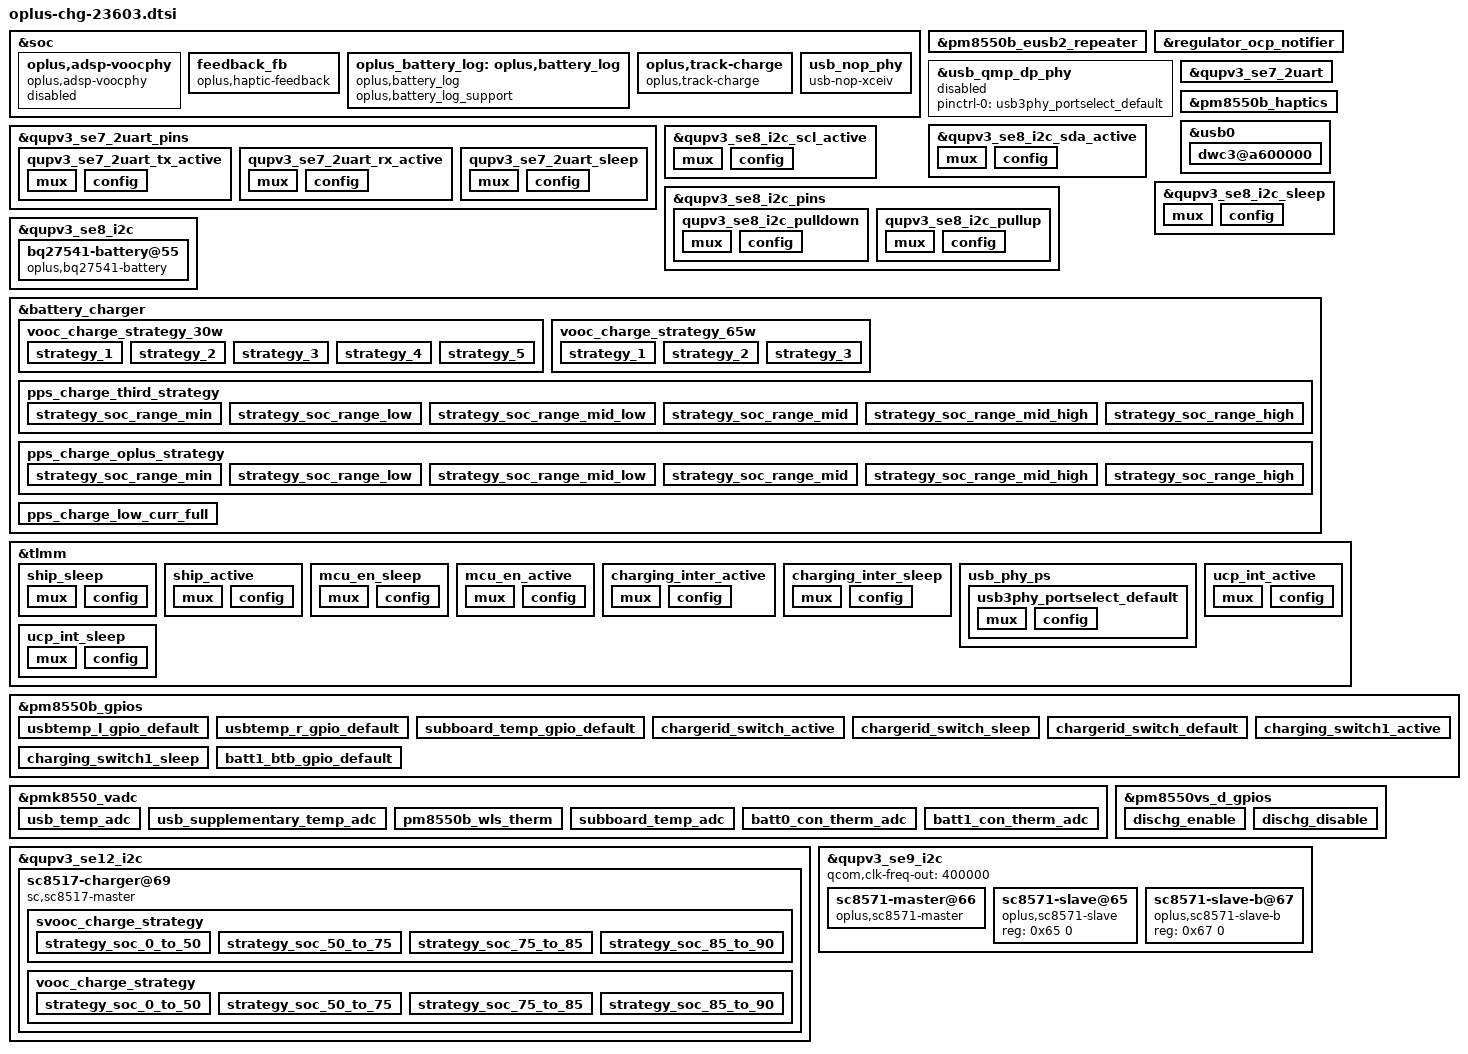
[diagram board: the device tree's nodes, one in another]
#include "oplus_chg_8550.h"
#include <dt-bindings/phy/qcom,usb3-4nm-qmp-combo.h>

//#ifdef OPLUS_FEATURE_CHG_BASIC /* BSP.CHG.Basic, 2020/05/20, sjc Add for charging */
&soc {
	oplus,adsp-voocphy {
		status = "disabled";
		compatible = "oplus,adsp-voocphy";
	};
};

&pm8550b_eusb2_repeater {
	qcom,param-override-seq = <0x00 0x50 0x0D 0x51 0x07 0x53 0x03 0x54
			0x03 0x55 0x00 0x56 0x07 0x57 0x2 0x58 0x3 0x59 0x1 0x5A 0x2 0x5B>;
	qcom,param-override-seq-host = <0x00 0x50 0x06 0x51 0x07 0x53 0x03 0x54
			0x00 0x55 0x00 0x56 0x02 0x57 0x2 0x58 0x3 0x59 0x1 0x5A 0x2 0x5B>;
};

&regulator_ocp_notifier {
	periph-1cb-supply = <0>;
	periph-1cc-supply = <0>;
	periph-1cd-supply = <0>;
	periph-4c1-supply = <0>;
	periph-4c3-supply = <0>;
};

&usb_qmp_dp_phy {
	pinctrl-names = "default";
	pinctrl-0 = <&usb3phy_portselect_default>;
	status = "disabled";
};

&qupv3_se7_2uart_pins {
	qupv3_se7_2uart_tx_active: qupv3_se7_2uart_tx_active {
		mux {
			pins = "gpio26";
			function = "qup1_se7_l2";
		};

		config {
			pins = "gpio26";
			drive-strength = <2>;
			bias-disable;
		};
	};

	qupv3_se7_2uart_rx_active: qupv3_se7_2uart_rx_active {
		mux {
			pins = "gpio27";
			function = "qup1_se7_l3";
		};

		config {
			pins = "gpio27";
			drive-strength = <2>;
			bias-disable;
		};
	};

	qupv3_se7_2uart_sleep: qupv3_se7_2uart_sleep {
		mux {
			pins = "gpio26", "gpio27";
			function = "gpio";
		};

		config {
			pins = "gpio26", "gpio27";
			drive-strength = <2>;
			bias-pull-down;
			input-enable;
		};
	};
};

&qupv3_se7_2uart {
	pinctrl-names = "default", "sleep";
	pinctrl-0 = <&qupv3_se7_2uart_tx_active>, <&qupv3_se7_2uart_rx_active>;
	pinctrl-1 = <&qupv3_se7_2uart_sleep>;
	status = "ok";
};

&pm8550b_haptics {
	qcom,vmax-mv = <1280>;
	qcom,cl-vmax-mv = <1280>;
	qcom,lra-period-us = <5882>;
	qcom,fifo-vmax-mv = <8000>;
	qcom,old-steady-vmax-mv = <8000>;
	qcom,cal-data-restore;
	qcom,vibrator-type = <809>;//ela0809
	qcom,drv-duty = <4>;//75%
};

&usb0 {
/delete-property/ extcon;
	dwc3@a600000 {
		usb-phy = <&eusb2_phy0>, <&usb_nop_phy>;
		maximum-speed = "high-speed";
		dr_mode = "otg";
	};
};

&qupv3_se8_i2c_sda_active {
	mux {
		pins = "gpio0";
		function = "qup2_se0_l0_mirb";
	};

	config {
		pins = "gpio0";
		drive-strength = <2>;
		bias-pull-up;
	};
};

&qupv3_se8_i2c_scl_active {
	mux {
		pins = "gpio1";
		function = "qup2_se0_l1_mirb";
	};

	config {
		pins = "gpio1";
		drive-strength = <2>;
		bias-pull-up;
	};
};

&qupv3_se8_i2c_sleep {
	mux {
		pins = "gpio0", "gpio1";
		function = "gpio";
	};

	config {
		pins = "gpio0", "gpio1";
		drive-strength = <2>;
		bias-disable;
	};
};

&qupv3_se8_i2c_pins {
	qupv3_se8_i2c_pulldown: qupv3_se8_i2c_pulldown {
		mux {
			pins = "gpio0", "gpio1";
			function = "gpio";
		};

		config {
			pins = "gpio0", "gpio1";
			drive-strength = <2>;
			bias-pull-down;
			output-low;
		};
	};

	qupv3_se8_i2c_pullup: qupv3_se8_i2c_pullup {
		mux {
			pins = "gpio0", "gpio1";
			function = "gpio";
		};

		config {
			pins = "gpio0", "gpio1";
			drive-strength = <2>;
			bias-pull-up;
			input-enable;
		};
	};
};

&qupv3_se8_i2c {
	status = "ok";
	qcom,clk-freq-out = <100000>;

	pinctrl-names = "default", "sleep", "pulldown", "pullup";
	pinctrl-0 = <&qupv3_se8_i2c_scl_active>,<&qupv3_se8_i2c_sda_active>;
	pinctrl-1 = <&qupv3_se8_i2c_sleep>;
	pinctrl-2 = <&qupv3_se8_i2c_pulldown>;
	pinctrl-3 = <&qupv3_se8_i2c_pullup>;

	bq27541-battery@55 {
		status = "okay";
		compatible = "oplus,bq27541-battery";
		reg = <0x55>;
		qcom,modify-soc-smooth;
		qcom,modify-soc-calibration;
		qcom,batt_bq28z610;
		qcom,sha1_key_index = <1>;
	};
};

&battery_charger {
	io-channels	= <&pmk8550_vadc PM8550B_ADC5_GEN3_AMUX2_GPIO5_100K_PU>,
					<&pmk8550_vadc PM8550B_ADC5_GEN3_AMUX_THM6_GPIO10_100K_PU>,
					<&pmk8550_vadc PM8550B_ADC5_GEN3_AMUX3_GPIO6_100K_PU>,
					<&pmk8550_vadc PM8550B_ADC5_GEN3_AMUX_THM4_USB_THERM_100K_PU>,
					<&pmk8550_vadc PM8550B_ADC5_GEN3_AMUX_THM1_BATT_THERM_100K_PU>;
	io-channel-names = "usb_temp_adc",
			"usb_supplementary_temp_adc",
			"subboard_temp_adc",
			"conn_therm",
			"batt0_con_therm_adc";

	oplus,ic_type = <OPLUS_CHG_IC_BUCK>;
	oplus,ic_index = <0>;

	//for oplus chg framework:
	oplus,chg_ops = "plat-pmic";
	qcom,smart_charging_screenoff;
	qcom,voocphy_support = <2>;
	qcom,input_current_charger_ma = <2000>;
	qcom,pd_input_current_charger_ma = <2000>;
	qcom,qc_input_current_charger_ma = <2000>;

	qcom,input_current_usb_ma = <500>;

	qcom,input_current_cdp_ma = <1500>;
	qcom,input_current_led_ma = <1200>;
	qcom,input_current_led_ma_high = <1200>;
	qcom,input_current_led_ma_warm = <1500>;
	qcom,input_current_led_ma_normal = <2000>;
	qcom,led_warm_bat_decidegc = <350>;
	qcom,led_high_bat_decidegc = <370>;

	qcom,input_current_camera_ma = <1200>;

	qcom,input_current_vooc_led_ma_high = <2200>;
	qcom,input_current_vooc_led_ma_warm = <3200>;
	qcom,input_current_vooc_led_ma_normal = <3600>;
	qcom,input_current_vooc_ma_normal = <3600>;
	qcom,vooc_temp_bat_normal_decidegc = <350>;
	qcom,input_current_vooc_ma_warm = <3200>;
	qcom,vooc_temp_bat_warm_decidegc = <370>;
	qcom,input_current_vooc_ma_high = <2200>;
	qcom,vooc_temp_bat_hot_decidegc = <530>;

	qcom,charger_current_vooc_ma_normal = <3600>;

	qcom,chg_ctrl_by_calling;
	qcom,input_current_calling_ma = <1500>;

	//qcom,input_current_led_ma_overtemp = <900>;
	qcom,iterm_ma = <122>;
	qcom,recharge-mv = <100>;
	qcom,batt_capacity_mah = <4600>;/*typical capacity*/
	//qcom,batt_capacity_mah = <4400>; /*rated capacity*/

	qcom,removed_bat_decidegc = <390>;  /*<-39C*/

	qcom,cold_bat_decidegc = <200>;  /*-20C~ -10C*/
	qcom,temp_cold_vfloat_mv = <4435>;//4.45v
	qcom,temp_cold_fastchg_current_ma_high = <600>;
	qcom,temp_cold_fastchg_current_ma_low = <400>;
	qcom,temp_cold_fastchg_current_ma = <400>;

	qcom,freeze_bat_decidegc = <100>;  /*-10C~0C*/
	qcom,temp_freeze_fastchg_current_ma_high = <1800>;
	qcom,temp_freeze_fastchg_current_ma_low = <600>;
	qcom,temp_freeze_fastchg_current_ma = <600>;
	//qcom,pd_temp_freeze_fastchg_current_ma_high = <900>;
	//qcom,pd_temp_freeze_fastchg_current_ma_low = <300>;
	//qcom,qc_temp_freeze_fastchg_current_ma_high = <900>;
	//qcom,qc_temp_freeze_fastchg_current_ma_low = <300>;

	qcom,little_cold_bat_decidegc = <0>;	/*0C~5C*/
	qcom,temp_little_cold_vfloat_mv = <4435>;
	qcom,temp_little_cold_fastchg_current_ma_high = <2200>;
	qcom,temp_little_cold_fastchg_current_ma_low = <2200>;
	qcom,temp_little_cold_fastchg_current_ma = <2200>;
	qcom,pd_temp_little_cold_fastchg_current_ma_high = <4000>;
	qcom,pd_temp_little_cold_fastchg_current_ma_low = <3200>;
	qcom,qc_temp_little_cold_fastchg_current_ma_high = <4000>;
	qcom,qc_temp_little_cold_fastchg_current_ma_low = <3200>;

	qcom,cool_bat_decidegc = <50>;	/*5C~12C*/
	qcom,temp_cool_vfloat_mv = <4435>;
	qcom,temp_cool_fastchg_current_ma_high = <2200>;
	qcom,temp_cool_fastchg_current_ma_low = <2200>;
	qcom,pd_temp_cool_fastchg_current_ma_high = <4000>;
	qcom,pd_temp_cool_fastchg_current_ma_low = <4000>;
	qcom,qc_temp_cool_fastchg_current_ma_high = <4000>;
	qcom,qc_temp_cool_fastchg_current_ma_low = <4000>;

	qcom,little_cool_bat_decidegc = <120>;	/*12C~16C*/
	qcom,temp_little_cool_vfloat_mv = <4435>;
	qcom,temp_little_cool_fastchg_current_ma = <2200>;
	qcom,pd_temp_little_cool_fastchg_current_ma = <4000>;
	qcom,qc_temp_little_cool_fastchg_current_ma = <4000>;

	qcom,normal_bat_decidegc = <160>;	/*16C~44C*/
	qcom,temp_normal_fastchg_current_ma = <2200>;
	qcom,temp_normal_vfloat_mv = <4435>;
	qcom,pd_temp_normal_fastchg_current_ma = <4000>;
	qcom,qc_temp_normal_fastchg_current_ma = <4000>;

	qcom,warm_bat_decidegc = <450>;		/*45C~53C*/ /*8pin Bat Vooc project need add 3 degree C*/
	qcom,temp_warm_vfloat_mv = <4130>;
	qcom,temp_warm_fastchg_current_ma = <2200>;
	qcom,pd_temp_warm_fastchg_current_ma = <2400>;
	qcom,qc_temp_warm_fastchg_current_ma = <2400>;
	qcom,temp_warm_fastchg_current_ma_led_on = <1000>;

	qcom,hot_bat_decidegc = <530>;

	qcom,non_standard_vfloat_mv = <3980>;
	qcom,non_standard_fastchg_current_ma = <1000>;

	qcom,short_c_bat_cv_mv = <4330>;
	qcom,short_c_bat_vfloat_mv = <3800>;
	qcom,short_c_bat_fastchg_current_ma = <1000>;

	qcom,cold_vfloat_sw_limit = <4385>;
	qcom,little_cold_vfloat_sw_limit = <4385>;
	qcom,cool_vfloat_sw_limit = <4385>;
	qcom,little_cool_vfloat_sw_limit = <4385>;
	qcom,normal_vfloat_sw_limit = <4385>;
	qcom,warm_vfloat_sw_limit = <4080>;
	qcom,non_standard_vfloat_sw_limit = <3930>;
	qcom,short_c_bat_vfloat_sw_limit = <3750>;

	qcom,max_chg_time_sec = <64800>;
	qcom,charger_hv_thr = <9900>;
	qcom,charger_recv_thr = <9500>;
	qcom,charger_lv_thr = <3400>;
	qcom,vbatt_full_thr = <4435>;
	qcom,vbatt_hv_thr = <4600>;
	qcom,vfloat_step_mv = <8>;
	qcom,non_standard_vfloat_over_sw_limit = <3990>;
	qcom,cold_vfloat_over_sw_limit = <4445>;
	qcom,little_cold_vfloat_over_sw_limit = <4445>;
	qcom,cool_vfloat_over_sw_limit = <4445>;
	qcom,little_cool_vfloat_over_sw_limit = <4445>;
	qcom,normal_vfloat_over_sw_limit = <4445>;
	qcom,warm_vfloat_over_sw_limit = <4140>;

	oplus,uart_tx-gpio = <&tlmm 26 0x00>;
	oplus,uart_rx-gpio = <&tlmm 27 0x00>;
	qcom,usbtemp_batt_temp_low = <50>;
	qcom,usbtemp_batt_temp_high = <50>;
	qcom,usbtemp_ntc_temp_low = <57>;
	qcom,usbtemp_ntc_temp_high = <69>;
	qcom,usbtemp_temp_gap_low_with_batt_temp = <7>;
	qcom,usbtemp_temp_gap_high_with_batt_temp = <12>;
	qcom,usbtemp_temp_gap_low_without_batt_temp = <12>;
	qcom,usbtemp_temp_gap_high_without_batt_temp = <24>;
	qcom.usbtemp_rise_fast_temp_low = <3>;
	qcom.usbtemp_rise_fast_temp_high = <3>;
	qcom.usbtemp_rise_fast_temp_count_low = <30>;
	qcom.usbtemp_rise_fast_temp_count_high = <20>;

	qcom,usbtemp_cool_down_ntc_low = <56>;
	qcom,usbtemp_cool_down_ntc_high = <67>;
	qcom,usbtemp_cool_down_gap_low = <12>;
	qcom,usbtemp_cool_down_gap_high = <20>;
	qcom,usbtemp_cool_down_recover_ntc_low = <48>;
	qcom,usbtemp_cool_down_recover_ntc_high = <60>;
	qcom,usbtemp_cool_down_recover_gap_low = <6>;
	qcom,usbtemp_cool_down_recover_gap_high = <15>;
	qcom,usbtemp_cool_down_recoup_high = <7>;
	qcom,usbtemp_cool_down_recoup_low = <2>;

	qcom,vbatt_power_off = <3300>;
	qcom,vbatt_soc_1 = <3310>;
	qcom,vooc_project = <16>;
	qcom,vbatt_num = <2>;
	qcom,ffc_support;
	qcom,dual_ffc;
	recharge_after_full;
	//qcom,wireless_support;
	//qcom,wpc_no_chargerpump;

	qcom,normal_vterm_hw_inc = <18>;
	qcom,non_normal_vterm_hw_inc = <18>;

	qcom,ff1_normal_fastchg_ma = <1100>;
	qcom,ff1_warm_fastchg_ma = <1100>;

	qcom,ffc2_normal_fastchg_ma = <700>;/*12C~35c*/
	qcom,ffc2_temp_warm_decidegc = <350>;
	qcom,ffc2_warm_fastchg_ma = <700>;/*35C~40c*/
	qcom,ffc2_temp_high_decidegc = <400>;
	qcom,ffc2_temp_low_decidegc = <120>;

	qcom,ff1_exit_step_ma = <700>;
	qcom,ff1_warm_exit_step_ma = <700>;
	qcom,ffc2_exit_step_ma = <300>;
	qcom,ffc2_warm_exit_step_ma = <300>;

	qcom,ffc_normal_vfloat_sw_limit = <4445>;
	qcom,ffc_temp_normal_vfloat_mv = <4500>;
	qcom,ffc1_temp_normal_vfloat_mv = <4500>;
	qcom,ffc1_normal_vfloat_over_sw_limit = <4500>;
	qcom,ffc_normal_vfloat_over_sw_limit = <4500>;
	qcom,ffc_warm_vfloat_sw_limit = <4445>;
	qcom,ffc_temp_warm_vfloat_mv = <4500>;
	qcom,ffc_warm_vfloat_over_sw_limit = <4500>;

	qcom,ffc2_normal_vfloat_sw_limit = <4440>;
	qcom,ffc2_temp_normal_vfloat_mv = <4500>;
	qcom,ffc2_normal_vfloat_over_sw_limit = <4500>;
	qcom,ffc2_warm_vfloat_sw_limit = <4435>;
	qcom,ffc2_temp_warm_vfloat_mv = <4500>;
	qcom,ffc2_warm_vfloat_over_sw_limit = <4500>;

	qcom,default_iterm_ma = <122>;
	qcom,default_temp_normal_fastchg_current_ma = <2200>;
	qcom,default_normal_vfloat_sw_limit = <4385>;
	qcom,default_temp_normal_vfloat_mv = <4435>;
	qcom,default_normal_vfloat_over_sw_limit = <4445>;

	qcom,default_temp_little_cool_fastchg_current_ma = <2200>;
	qcom,default_little_cool_vfloat_sw_limit = <4385>;
	qcom,default_temp_little_cool_vfloat_mv = <4435>;
	qcom,default_little_cool_vfloat_over_sw_limit = <4445>;
	qcom,fg_info_package_read_support;/*for oplus_chg_get_props_from_adsp_by_buffer() to read*/

	///qcom,offset_temp = <30>;
	//for control:
	//qcom,suspend_after_full;
	qcom,check_batt_full_by_sw;
	qcom,external_gauge;
	qcom,chg_ctrl_by_lcd;
	qcom,chg_ctrl_by_vooc;
	qcom,chg_ctrl_by_camera;
	qcom,sw_vfloat_over_protect_enable;
	qcom,usbtemp_batttemp_gap = <12>;
	qcom,usbtemp_change_gap;
	oplus,aging_ffc_version = <1>;
	qcom,support_usbtemp_protect_v2;
	qcom,support_abnormal_adapter;
	oplus,adsp_chg_use_ap_gauge;

	//for PD9V or QC9V
	//qcom,vbatt_pdqc_to_5v_thr = <4100>;
	qcom,vbatt_pdqc_to_9v_thr = <5000>;/*always 9v*/
	//for smart charge begin
	//qcom,smart_chg_bcc_support;
	//for smart charge end
	qcom,smart_chg_soh_support;
	oplus,quick_mode_gain_support;
	qcom,vooc_show_ui_soc_decimal;
	qcom,ui_soc_decimal_speedmin = <20>;//2A
	oplus,smooth_switch_v2;
	oplus,reserve_chg_soc = <3>;
	oplus,reserve_dis_soc = <3>;
	qcom,otg_scheme = <0>;//0:cid 1:ccdetect_gpio 2:switch
	qcom,otg_boost_src = <0>;//0:plat_pmic 1:external
	qcom,support_3p6_standard;

	qcom,chargerid_switch-gpio = <&pm8550b_gpios 2 0x00>;
	qcom,dischg-gpio = <&pm8550vs_d_gpios 5 0x00>;
	qcom,ship-gpio = <&tlmm 178 0x00>;
	qcom,mcu-en-gpio = <&tlmm 67 0x00>; //use rk826 to enter shipmode
	pinctrl-names = "dischg_enable", "dischg_disable",
					"chargerid_switch_active", "chargerid_switch_sleep","chargerid_switch_default",
					"usbtemp_l_gpio_default", "usbtemp_r_gpio_default",
					"subboard_temp_gpio_default", "mcu_en_active", "mcu_en_sleep",
					"ship_active", "ship_sleep", "batt1_btb_gpio_default";
	pinctrl-0 = <&dischg_enable>;
	pinctrl-1 = <&dischg_disable>;
	pinctrl-2 = <&chargerid_switch_active>;
	pinctrl-3 = <&chargerid_switch_sleep>;
	pinctrl-4 = <&chargerid_switch_default>;
	pinctrl-5 = <&usbtemp_l_gpio_default>;
	pinctrl-6 = <&usbtemp_r_gpio_default>;
	pinctrl-7 = <&subboard_temp_gpio_default>;
	pinctrl-8 = <&mcu_en_active>;
	pinctrl-9 = <&mcu_en_sleep>;
	pinctrl-10 = <&ship_active>;
	pinctrl-11 = <&ship_sleep>;
	pinctrl-12 = <&batt1_btb_gpio_default>;

	qcom,vooc-max-input-volt-support = <11000>;     //11V
	qcom,vooc-max-input-current-support = <9100>;   //9.1A
	vooc_charge_strategy_30w {
		strategy_1 {
			capacity_range = <0 75>;
			temp_range = <120 160>;
			input_current = <4000 4450 0
					3000 4470 0
					2000 4480 0>;
			};
		strategy_2 {
			capacity_range = <0 75>;
			temp_range = <160 410>;
			input_current = <6000 4200 900
					5000 4200 0
					4500 4450 0
					4000 4450 0
					3000 4470 0
					2000 4480 0>;
		};
		strategy_3 {
			capacity_range = <0 75>;
			temp_range = <410 420>;
			input_current = <4000 4470 0
					2000 4480 0>;
		};
		strategy_4 {
			capacity_range = <0 75>;
			temp_range = <420 425>;
			input_current = <4000 4480 0>;
		};
		strategy_5 {
			capacity_range = <0 75>;
			temp_range = <425 435>;
			input_current = <3000 4480 0>;
		};
	};

	vooc_charge_strategy_65w {
		strategy_1 {
			capacity_range = <0 50>;
			temp_range = <120 160>;
			input_current = <6000 4200 0
					4000 4454 0
					2000 4494 0
					1500 4500 0>;
		};
		strategy_2 {
			capacity_range = <0 50>;
			temp_range = <160 370>;
			input_current = <6500 4200 0
					6000 4250 300
					5500 4300 400
					4500 4454 780
					3500 4454 0
					2000 4494 0
					1500 4500 0>;
		};
		strategy_3 {
			capacity_range = <0 90>;
			temp_range = <370 430>;
			input_current = <6500 4200 0
					6000 4250 300
					5500 4300 400
					4500 4454 780
					3500 4454 0
					2000 4494 0
					1600 4500 0>;
		};
	};
};

/*#ifdef OPLUS_FEATURE_CHG_BASIC*/
/* BSP.CHG.Basic, 2021/09/20, Add for pps 240 */
&battery_charger {
	oplus,pps_ops = "cp-sc8571";
	qcom,smart_chg_bcc_support;
	oplus,pps_support_type = <3>;
	oplus,pps_support_third = <0>;
	oplus,pps_warm_allow_vol = <4000>;
	oplus,pps_warm_allow_soc = <50>;
	oplus,pps_strategy_normal_current = <12000>;//6A
	oplus,pps_strategy_normal_bypass_limit_current = <8100>;
	oplus,pps_over_high_or_low_current = <12000>;
	oplus,pps_timeout_third = <10800>;
	oplus,pps_timeout_oplus = <10800>;
	oplus,pps_ibat_over_third = <4000>;
	oplus,pps_ibat_over_oplus = <25000>;
	oplus,pps_full_cool_sw_vbat = <4430>;
	oplus,pps_full_normal_sw_vbat = <4490>;//4490
	oplus,pps_full_normal_hw_vbat = <4505>;//4500
	oplus,pps_full_ffc_vbat = <4420>;
	oplus,pps_full_warm_vbat = <4130>;
	oplus,pps_full_cool_sw_vbat_third = <4430>;
	oplus,pps_full_normal_sw_vbat_third= <4430>;
	oplus,pps_full_normal_hw_vbat_third = <4440>;
	oplus,pps_bcc_max_curr = <15000>;
	oplus,pps_bcc_min_curr = <1000>;
	oplus,pps_bcc_exit_curr = <1000>;
	oplus,pps_switch_soc_v2 = <95>;
	oplus,pps_switch_power_v2 = <30>;
	oplus,pps_switch_soc_v3 = <85>;
	oplus,pps_switch_power_v3 = <80>;
	oplus,pps_r_default = <90 10 30 30 15 30 15>;
	oplus,pps_rmos_mohm = <4>;
	oplus,pps_r_limit = <280 200 140 90 50>;
	oplus,pps_strategy_batt_high_temp = <425 437 445 415 425 437>;
	oplus,pps_strategy_high_current = <4500 2500 1500 6000 4500 2500>;
	oplus,pps_charge_strategy_soc = <0 30 55 75 85 90 95>;
	oplus,pps_charge_strategy_temp = <0 50 120 200 350 445 510>;
	oplus,pps_low_curr_full_strategy_temp = <120 200 350 445>;

	pps_charge_third_strategy {
		strategy_soc_range_min {
			strategy_temp_little_cold =	<11000 4150 1300 0 0
							 11000 4200 1100 0 0
							 11000 4420 650 0 0
							 11000 4430 500 1 0>;
			strategy_temp_cool =		<11000 4150 1300 0 0
							 11000 4200 1100 0 0
							 11000 4420 650 0 0
							 11000 4430 500 1 0>;
			strategy_temp_little_cool =	<11000 4420 1500 0 0
							 11000 4420 1400 0 0
							 11000 4420 1200 0 0
							 11000 4420 1000 0 0
							 11000 4420 800 0 0
							 11000 4420 550 0 0
							 11000 4430 450 1 0>;
			strategy_temp_normal_low =	<11000 4420 1450 0 0
							 11000 4420 1350 0 0
							 11000 4420 1250 0 0
							 11000 4420 1150 0 0
							 11000 4420 1050 0 0
							 11000 4430 1000 1 0>;
			strategy_temp_normal_high =	<11000 4420 1450 0 0
							 11000 4420 1350 0 0
							 11000 4420 1250 0 0
							 11000 4420 1150 0 0
							 11000 4420 1050 0 0
							 11000 4430 1000 1 0>;
			strategy_temp_warm =		<11000 4130 600 1 0>;
		};
		strategy_soc_range_low {
			strategy_temp_little_cold =	<11000 4150 1300 0 0
							 11000 4200 1100 0 0
							 11000 4420 650 0 0
							 11000 4430 500 1 0>;
			strategy_temp_cool =		<11000 4150 1300 0 0
							 11000 4200 1100 0 0
							 11000 4420 650 0 0
							 11000 4430 500 1 0>;
			strategy_temp_little_cool =	<11000 4420 1500 0 0
							 11000 4420 1400 0 0
							 11000 4420 1200 0 0
							 11000 4420 1000 0 0
							 11000 4420 800 0 0
							 11000 4420 550 0 0
							 11000 4430 450 1 0>;
			strategy_temp_normal_low =	<11000 4420 1450 0 0
							 11000 4420 1350 0 0
							 11000 4420 1250 0 0
							 11000 4420 1150 0 0
							 11000 4420 1050 0 0
							 11000 4430 1000 1 0>;
			strategy_temp_normal_high =	<11000 4420 1450 0 0
							 11000 4420 1350 0 0
							 11000 4420 1250 0 0
							 11000 4420 1150 0 0
							 11000 4420 1050 0 0
							 11000 4430 1000 1 0>;
			strategy_temp_warm =		<11000 4130 600 1 0>;
		};
		strategy_soc_range_mid_low {
			strategy_temp_little_cold =	<11000 4150 1300 0 0
							 11000 4200 1100 0 0
							 11000 4420 650 0 0
							 11000 4430 500 1 0>;
			strategy_temp_cool =		<11000 4150 1300 0 0
							 11000 4200 1100 0 0
							 11000 4420 650 0 0
							 11000 4430 500 1 0>;
			strategy_temp_little_cool =	<11000 4420 1500 0 0
							 11000 4420 1400 0 0
							 11000 4420 1200 0 0
							 11000 4420 1000 0 0
							 11000 4420 800 0 0
							 11000 4420 550 0 0
							 11000 4430 450 1 0>;
			strategy_temp_normal_low =	<11000 4420 1450 0 0
							 11000 4420 1350 0 0
							 11000 4420 1250 0 0
							 11000 4420 1150 0 0
							 11000 4420 1050 0 0
							 11000 4430 1000 1 0>;
			strategy_temp_normal_high =	<11000 4420 1450 0 0
							 11000 4420 1350 0 0
							 11000 4420 1250 0 0
							 11000 4420 1150 0 0
							 11000 4420 1050 0 0
							 11000 4430 1000 1 0>;
			strategy_temp_warm =		<11000 4130 600 1 0>;
		};
		strategy_soc_range_mid {
			strategy_temp_little_cold =	<11000 4150 1300 0 0
							 11000 4200 1100 0 0
							 11000 4420 650 0 0
							 11000 4430 500 1 0>;
			strategy_temp_cool =		<11000 4150 1300 0 0
							 11000 4200 1100 0 0
							 11000 4420 650 0 0
							 11000 4430 500 1 0>;
			strategy_temp_little_cool =	<11000 4420 1500 0 0
							 11000 4420 1400 0 0
							 11000 4420 1200 0 0
							 11000 4420 1000 0 0
							 11000 4420 800 0 0
							 11000 4420 550 0 0
							 11000 4430 450 1 0>;
			strategy_temp_normal_low =	<11000 4420 1450 0 0
							 11000 4420 1350 0 0
							 11000 4420 1250 0 0
							 11000 4420 1150 0 0
							 11000 4420 1050 0 0
							 11000 4430 1000 1 0>;
			strategy_temp_normal_high =	<11000 4420 1450 0 0
							 11000 4420 1350 0 0
							 11000 4420 1250 0 0
							 11000 4420 1150 0 0
							 11000 4420 1050 0 0
							 11000 4430 1000 1 0>;
			strategy_temp_warm =		<11000 4130 600 1 0>;
		};
		strategy_soc_range_mid_high {
			strategy_temp_little_cold =	<11000 4200 1100 0 0
							 11000 4420 650 0 0
							 11000 4430 500 1 0>;
			strategy_temp_cool =		<11000 4200 1100 0 0
							 11000 4420 650 0 0
							 11000 4430 500 1 0>;
			strategy_temp_little_cool =	<11000 4420 1500 0 0
							 11000 4420 1400 0 0
							 11000 4420 1200 0 0
							 11000 4420 1000 0 0
							 11000 4420 800 0 0
							 11000 4420 550 0 0
							 11000 4430 450 1 0>;
			strategy_temp_normal_low =	<11000 4420 1450 0 0
							 11000 4420 1350 0 0
							 11000 4420 1250 0 0
							 11000 4420 1150 0 0
							 11000 4420 1050 0 0
							 11000 4430 1000 1 0>;
			strategy_temp_normal_high =	<11000 4420 1450 0 0
							 11000 4420 1350 0 0
							 11000 4420 1250 0 0
							 11000 4420 1150 0 0
							 11000 4420 1050 0 0
							 11000 4430 1000 1 0>;
			strategy_temp_warm =		<11000 4130 600 1 0>;
		};
		strategy_soc_range_high {
			strategy_temp_little_cold =	<11000 4420 650 0 0
							 11000 4430 500 1 0>;
			strategy_temp_cool =		<11000 4420 650 0 0
							 11000 4430 500 1 0>;
			strategy_temp_little_cool =	<11000 4420 1400 0 0
							 11000 4420 1200 0 0
							 11000 4420 1000 0 0
							 11000 4420 800 0 0
							 11000 4420 550 0 0
							 11000 4430 450 1 0>;
			strategy_temp_normal_low =	<11000 4420 1450 0 0
							 11000 4420 1350 0 0
							 11000 4420 1250 0 0
							 11000 4420 1150 0 0
							 11000 4420 1050 0 0
							 11000 4430 1000 1 0>;
			strategy_temp_normal_high =	<11000 4420 1450 0 0
							 11000 4420 1350 0 0
							 11000 4420 1250 0 0
							 11000 4420 1150 0 0
							 11000 4420 1050 0 0
							 11000 4430 1000 1 0>;
			strategy_temp_warm =		<11000 4130 600 1 0>;
		};
	};

	pps_charge_oplus_strategy {
		strategy_soc_range_min {
			strategy_temp_little_cold =	<11000 4150 1300 0 0
							 11000 4200 1100 0 0
							 11000 4490 650 0 0
							 11000 4490 450 1 0>;
			strategy_temp_cool = 		<11000 4150 1300 0 0
							 11000 4200 1100 0 0
							 11000 4490 650 0 0
							 11000 4490 450 1 0>;
			strategy_temp_little_cool =	<20000 4160 4500 0 0
							 20000 4280 4250 0 0
							 20000 4280 3750 0 0
							 20000 4430 3200 0 0
							 20000 4430 2500 0 0
							 20000 4490 2100 0 0
							 20000 4490 1750 0 0
							 20000 4490 1500 0 0
							 20000 4490 1400 0 0
							 20000 4490 1200 0 0
							 20000 4490 1000 0 0
							 20000 4490 800 0 0
							 20000 4490 550 0 0
							 20000 4490 450 1 0>;
			strategy_temp_normal_low =	<20000 4220 12000 0 60
							 20000 4220 9000 0 60
							 20000 4220 8000 0 60
							 20000 4440 6500 0 300
							 20000 4440 5500 0 60
							 20000 4440 4750 0 0
							 20000 4440 4500 0 0
							 20000 4490 4250 0 0
							 20000 4490 4000 0 0
							 20000 4490 3750 0 0
							 20000 4490 3500 0 0
							 20000 4490 3250 0 0
							 20000 4490 3000 0 0
							 20000 4490 2750 0 0
							 20000 4490 2650 0 0
							 20000 4490 2550 0 0
							 20000 4490 2450 0 0
							 20000 4490 2350 0 0
							 20000 4490 2250 0 0
							 20000 4490 2150 0 0
							 20000 4490 2050 0 0
							 20000 4490 1950 0 0
							 20000 4490 1850 0 0
							 20000 4490 1750 0 0
							 20000 4490 1650 0 0
							 20000 4490 1550 0 0
							 20000 4490 1450 0 0
							 20000 4490 1350 0 0
							 20000 4490 1250 0 0
							 20000 4490 1150 0 0
							 20000 4490 1050 0 0
							 20000 4490 1000 1 0>;
			strategy_temp_normal_high =	<20000 4220 12000 0 60
							 20000 4220 9000 0 60
							 20000 4220 8000 0 60
							 20000 4440 6500 0 300
							 20000 4440 5500 0 60
							 20000 4440 4750 0 0
							 20000 4440 4500 0 0
							 20000 4490 4250 0 0
							 20000 4490 4000 0 0
							 20000 4490 3750 0 0
							 20000 4490 3500 0 0
							 20000 4490 3250 0 0
							 20000 4490 3000 0 0
							 20000 4490 2750 0 0
							 20000 4490 2650 0 0
							 20000 4490 2550 0 0
							 20000 4490 2450 0 0
							 20000 4490 2350 0 0
							 20000 4490 2250 0 0
							 20000 4490 2150 0 0
							 20000 4490 2050 0 0
							 20000 4490 1950 0 0
							 20000 4490 1850 0 0
							 20000 4490 1750 0 0
							 20000 4490 1650 0 0
							 20000 4490 1550 0 0
							 20000 4490 1500 1 0>;
			strategy_temp_warm = 		<11000 4130 600 1 0>;
		};
		strategy_soc_range_low {
			strategy_temp_little_cold =	<11000 4150 1300 0 0
							 11000 4200 1100 0 0
							 11000 4490 650 0 0
							 11000 4490 450 1 0>;
			strategy_temp_cool = 		<11000 4150 1300 0 0
							 11000 4200 1100 0 0
							 11000 4490 650 0 0
							 11000 4490 450 1 0>;
			strategy_temp_little_cool =	<20000 4430 3200 0 0
							 20000 4430 2500 0 0
							 20000 4490 2100 0 0
							 20000 4490 1750 0 0
							 20000 4490 1500 0 0
							 20000 4490 1400 0 0
							 20000 4490 1200 0 0
							 20000 4490 1000 0 0
							 20000 4490 800 0 0
							 20000 4490 550 0 0
							 20000 4490 450 1 0>;
			strategy_temp_normal_low =	<20000 4440 6500 0 300
							 20000 4440 5500 0 60
							 20000 4440 4750 0 0
							 20000 4440 4500 0 0
							 20000 4490 4250 0 0
							 20000 4490 4000 0 0
							 20000 4490 3750 0 0
							 20000 4490 3500 0 0
							 20000 4490 3250 0 0
							 20000 4490 3000 0 0
							 20000 4490 2750 0 0
							 20000 4490 2650 0 0
							 20000 4490 2550 0 0
							 20000 4490 2450 0 0
							 20000 4490 2350 0 0
							 20000 4490 2250 0 0
							 20000 4490 2150 0 0
							 20000 4490 2050 0 0
							 20000 4490 1950 0 0
							 20000 4490 1850 0 0
							 20000 4490 1750 0 0
							 20000 4490 1650 0 0
							 20000 4490 1550 0 0
							 20000 4490 1450 0 0
							 20000 4490 1350 0 0
							 20000 4490 1250 0 0
							 20000 4490 1150 0 0
							 20000 4490 1050 0 0
							 20000 4490 1000 1 0>;
			strategy_temp_normal_high =	<20000 4220 8000 0 30
							 20000 4440 6500 0 300
							 20000 4440 5500 0 60
							 20000 4440 4750 0 0
							 20000 4440 4500 0 0
							 20000 4490 4250 0 0
							 20000 4490 4000 0 0
							 20000 4490 3750 0 0
							 20000 4490 3500 0 0
							 20000 4490 3250 0 0
							 20000 4490 3000 0 0
							 20000 4490 2750 0 0
							 20000 4490 2650 0 0
							 20000 4490 2550 0 0
							 20000 4490 2450 0 0
							 20000 4490 2350 0 0
							 20000 4490 2250 0 0
							 20000 4490 2150 0 0
							 20000 4490 2050 0 0
							 20000 4490 1950 0 0
							 20000 4490 1850 0 0
							 20000 4490 1750 0 0
							 20000 4490 1650 0 0
							 20000 4490 1550 0 0
							 20000 4490 1500 1 0>;
			strategy_temp_warm = 		<11000 4130 600 1 0>;
		};
		strategy_soc_range_mid_low {
			strategy_temp_little_cold =	<11000 4150 1300 0 0
							 11000 4200 1100 0 0
							 11000 4490 650 0 0
							 11000 4490 450 1 0>;
			strategy_temp_cool = 		<11000 4150 1300 0 0
							 11000 4200 1100 0 0
							 11000 4490 650 0 0
							 11000 4490 450 1 0>;
			strategy_temp_little_cool = 	<20000 4430 2500 0 0
							 20000 4490 2100 0 0
							 20000 4490 1750 0 0
							 20000 4490 1500 0 0
							 20000 4490 1400 0 0
							 20000 4490 1200 0 0
							 20000 4490 1000 0 0
							 20000 4490 800 0 0
							 20000 4490 550 0 0
							 20000 4490 450 1 0>;
			strategy_temp_normal_low =	<20000 4490 3750 0 0
							 20000 4490 3500 0 0
							 20000 4490 3250 0 0
							 20000 4490 3000 0 0
							 20000 4490 2750 0 0
							 20000 4490 2650 0 0
							 20000 4490 2550 0 0
							 20000 4490 2450 0 0
							 20000 4490 2350 0 0
							 20000 4490 2250 0 0
							 20000 4490 2150 0 0
							 20000 4490 2050 0 0
							 20000 4490 1950 0 0
							 20000 4490 1850 0 0
							 20000 4490 1750 0 0
							 20000 4490 1650 0 0
							 20000 4490 1550 0 0
							 20000 4490 1450 0 0
							 20000 4490 1350 0 0
							 20000 4490 1250 0 0
							 20000 4490 1150 0 0
							 20000 4490 1050 0 0
							 20000 4490 1000 1 0>;
			strategy_temp_normal_high =	<20000 4430 4750 0 0
							 20000 4430 4500 0 0
							 20000 4490 4250 0 0
							 20000 4490 4000 0 0
							 20000 4490 3750 0 0
							 20000 4490 3500 0 0
							 20000 4490 3250 0 0
							 20000 4490 3000 0 0
							 20000 4490 2750 0 0
							 20000 4490 2650 0 0
							 20000 4490 2550 0 0
							 20000 4490 2450 0 0
							 20000 4490 2350 0 0
							 20000 4490 2250 0 0
							 20000 4490 2150 0 0
							 20000 4490 2050 0 0
							 20000 4490 1950 0 0
							 20000 4490 1850 0 0
							 20000 4490 1750 0 0
							 20000 4490 1650 0 0
							 20000 4490 1550 0 0
							 20000 4490 1500 1 0>;
			strategy_temp_warm = 		<11000 4130 600 1 0>;
		};
		strategy_soc_range_mid {
			strategy_temp_little_cold =	<11000 4200 1100 0 0
							 11000 4490 650 0 0
							 11000 4490 450 1 0>;
			strategy_temp_cool = 		<11000 4150 1300 0 0
							 11000 4200 1100 0 0
							 11000 4490 650 0 0
							 11000 4490 450 1 0>;
			strategy_temp_little_cool =	<20000 4490 2100 0 0
							 20000 4490 1750 0 0
							 20000 4490 1500 0 0
							 20000 4490 1400 0 0
							 20000 4490 1200 0 0
							 20000 4490 1000 0 0
							 20000 4490 800 0 0
							 20000 4490 550 0 0
							 20000 4490 450 1 0>;
			strategy_temp_normal_low =	<20000 4490 3000 0 0
			                                 20000 4490 2750 0 0
							 20000 4490 2650 0 0
							 20000 4490 2550 0 0
							 20000 4490 2450 0 0
							 20000 4490 2350 0 0
							 20000 4490 2250 0 0
							 20000 4490 2150 0 0
							 20000 4490 2050 0 0
							 20000 4490 1950 0 0
							 20000 4490 1850 0 0
							 20000 4490 1750 0 0
							 20000 4490 1650 0 0
							 20000 4490 1550 0 0
							 20000 4490 1450 0 0
							 20000 4490 1350 0 0
							 20000 4490 1250 0 0
							 20000 4490 1150 0 0
							 20000 4490 1050 0 0
							 20000 4490 1000 1 0>;
			strategy_temp_normal_high =	<20000 4490 4000 0 0
							 20000 4490 3750 0 0
							 20000 4490 3250 0 0
							 20000 4490 3000 0 0
							 20000 4490 2750 0 0
							 20000 4490 2650 0 0
							 20000 4490 2550 0 0
							 20000 4490 2450 0 0
							 20000 4490 2350 0 0
							 20000 4490 2250 0 0
							 20000 4490 2150 0 0
							 20000 4490 2050 0 0
							 20000 4490 1950 0 0
							 20000 4490 1850 0 0
							 20000 4490 1750 0 0
							 20000 4490 1650 0 0
							 20000 4490 1550 0 0
							 20000 4490 1500 1 0>;
			strategy_temp_warm = 		<11000 4130 600 1 0>;
		};
		strategy_soc_range_mid_high {
			strategy_temp_little_cold =	<11000 4200 1100 0 0
							 11000 4490 650 0 0
							 11000 4490 450 1 0>;
			strategy_temp_cool = 		<11000 4200 1100 0 0
							 11000 4490 650 0 0
							 11000 4490 450 1 0>;
			strategy_temp_little_cool =	<11000 4490 1500 0 0
							 11000 4490 1400 0 0
							 11000 4490 1200 0 0
							 11000 4490 1000 0 0
							 11000 4490 800 0 0
							 11000 4490 550 0 0
							 11000 4490 450 1 0>;
			strategy_temp_normal_low =	<20000 4490 2650 0 0
							 20000 4490 2550 0 0
							 20000 4490 2450 0 0
							 20000 4490 2350 0 0
							 20000 4490 2250 0 0
							 20000 4490 2150 0 0
							 20000 4490 2050 0 0
							 20000 4490 1950 0 0
							 20000 4490 1850 0 0
							 20000 4490 1750 0 0
							 20000 4490 1650 0 0
							 20000 4490 1550 0 0
							 20000 4490 1450 0 0
							 20000 4490 1350 0 0
							 20000 4490 1250 0 0
							 20000 4490 1150 0 0
							 20000 4490 1050 0 0
							 20000 4490 1000 1 0>;
			strategy_temp_normal_high =	 <20000 4490 3000 0 0
							 20000 4490 2750 0 0
							 20000 4490 2650 0 0
							 20000 4490 2550 0 0
							 20000 4490 2450 0 0
							 20000 4490 2350 0 0
							 20000 4490 2250 0 0
							 20000 4490 2150 0 0
							 20000 4490 2050 0 0
							 20000 4490 1950 0 0
							 20000 4490 1850 0 0
							 20000 4490 1750 0 0
							 20000 4490 1650 0 0
							 20000 4490 1550 0 0
							 20000 4490 1500 1 0>;
			strategy_temp_warm = 		<11000 4130 600 1 0>;
		};
		strategy_soc_range_high {
			strategy_temp_little_cold =	<11000 4490 650 0 0
							 11000 4490 450 1 0>;
			strategy_temp_cool = 		<11000 4490 650 0 0
							 11000 4490 450 1 0>;
			strategy_temp_little_cool =	<11000 4490 1000 0 0
							 11000 4490 800 0 0
							 11000 4490 550 0 0
							 11000 4490 450 1 0>;
			strategy_temp_normal_low =	<11000 4490 1550 0 0
							 11000 4490 1450 0 0
							 11000 4490 1350 0 0
							 11000 4490 1250 0 0
							 11000 4490 1150 0 0
							 11000 4490 1050 0 0
							 11000 4490 1000 1 0>;
			strategy_temp_normal_high =	 <11000 4490 1750 0 0
							 11000 4490 1650 0 0
							 11000 4490 1550 0 0
							 11000 4490 1500 1 0>;
			strategy_temp_warm =		<11000 4130 600 1 0>;
		};
	};

	pps_charge_low_curr_full {
		strategy_temp_little_cool = 	<800 4490 0
						 750 4480 0
						 650 4470 0
						 550 4460 0
						 450 4450 1>;
		strategy_temp_normal_low =	<1800 4490 0
						 1700 4485 0
						 1600 4470 0
						 1400 4460 0
						 1200 4450 1>;
		strategy_temp_normal_high = 	<2800 4490 0
						 2700 4485 0
						 2200 4470 0
						 1800 4460 0
						 1500 4450 1>;
	};
};
/*endif OPLUS_FEATURE_CHG_BASIC*/
&tlmm {
	ship_sleep: ship_sleep {
		mux {
			pins = "gpio178";
			function = "gpio";
		};

		config {
			pins = "gpio178";
			drive-strength = <2>;
			bias-pull-down;
			output-low;
		};
	};

	ship_active: ship_active {
		mux {
			pins = "gpio178";
			function = "gpio";
		};

		config {
			pins = "gpio178";
			drive-strength = <2>;
			bias-pull-up;
			output-high;
		};
	};

	mcu_en_sleep: mcu_en_sleep {
		mux {
			pins = "gpio67";
			function = "gpio";
		};

		config {
			pins = "gpio67";
			drive-strength = <2>;
			bias-pull-down;
			output-low;
		};
	};

	mcu_en_active: mcu_en_active {
		mux {
			pins = "gpio67";
			function = "gpio";
		};

		config {
			pins = "gpio67";
			drive-strength = <2>;
			bias-pull-up;
			output-high;
		};
	};
	charging_inter_active: charging_inter_active {
		mux {
			pins = "gpio9";
			function = "gpio";
		};
		config {
			pins = "gpio9";
			bias-pull-up; /* NO pull */
			drive-strength = <2>; /* 2 MA */
			input-enable;
		};
	};

	charging_inter_sleep: charging_inter_sleep {
		mux {
			pins = "gpio9";
			function = "gpio";
		};
		config {
			pins = "gpio9";
			bias-pull-up; /* NO pull */
			drive-strength = <2>; /* 2 MA */
			input-enable;
		};
	};
};

&tlmm {
	usb_phy_ps: usb_phy_ps {
		usb3phy_portselect_default: usb3phy_portselect_default {
			mux {
				pins = "gpio11";
				function = "usb_phy";
			};

			config {
				pins = "gpio11";
				bias-pull-down;
				drive-strength = <2>;
			};
		};
	};
};

&tlmm {
	ucp_int_active: ucp_int_active {
		mux {
			pins = "gpio14";
			function = "normal";
		};

		config {
			pins = "gpio14";
			drive-strength = <2>;
			bias-disable;
		};
	};
	ucp_int_sleep: ucp_int_sleep {
		mux {
			pins = "gpio14";
			function = "normal";
		};

		config {
			pins = "gpio14";
			drive-strength = <2>;
			bias-disable;
		};
	};
};


&pm8550b_gpios {
	usbtemp_l_gpio_default: usbtemp_l_gpio_default {
		pins = "gpio5"; //GPIO 5
		function = "normal"; //normal
		bias-high-impedance; //DISABLE GPIO5 for ADC
		bias-disable;
	};
	usbtemp_r_gpio_default: usbtemp_r_gpio_default {
		pins = "gpio10"; //GPIO 10
		function = "normal"; //normal
		bias-high-impedance; //DISABLE GPIO10 for ADC
		bias-disable;
	};
	subboard_temp_gpio_default: subboard_temp_gpio_default {
		pins = "gpio6"; /* GPIO 6 */
		function = "normal"; /* normal */
		bias-high-impedance; /* DISABLE GPIO5 for ADC*/
	};
	chargerid_switch_active: chargerid_switch_active {
		pins = "gpio2";
		function = "normal";
		bias-disable;
		power-source = <0>;
		output-high;
		qcom,drive-strength = <3>;
	};
	chargerid_switch_sleep: chargerid_switch_sleep {
		pins = "gpio2";
		function = "normal";
		bias-disable;
		power-source = <0>;
		output-low;
		qcom,drive-strength = <3>;
	};
	chargerid_switch_default: chargerid_switch_default {
		pins = "gpio2";
		function = "normal";
		bias-disable;
		power-source = <0>;
		output-low;
		qcom,drive-strength = <3>;
	};

	charging_switch1_active: charging_switch1_active {
		pins = "gpio8";
		function = "normal";
		bias-disable;
		power-source = <0>;
		output-high;
		qcom,drive-strength = <3>;
	};
	charging_switch1_sleep: charging_switch1_sleep {
		pins = "gpio8";
		function = "normal";
		bias-disable;
		power-source = <0>;
		output-low;
		qcom,drive-strength = <3>;
	};
	batt1_btb_gpio_default: batt1_btb_gpio_default {
		pins = "gpio12"; //GPIO 12
		function = "normal"; //normal
		bias-high-impedance; //DISABLE GPIO12 for ADC
		bias-disable;
	};
};

&pmk8550_vadc {
	usb_temp_adc {
		reg = <PM8550B_ADC5_GEN3_AMUX2_GPIO5_100K_PU>;
		label = "usb_temp_adc";
		qcom,pre-scaling = <1 1>;
		qcom,ratiometric;
		qcom,hw-settle-time = <200>;
		qcom,scale-fn-type = <OPLUS_ADC_SCALE_HW_CALIB_DEFAULT>;
	};
	usb_supplementary_temp_adc {
		reg = <PM8550B_ADC5_GEN3_AMUX_THM6_GPIO10_100K_PU>;
		label = "usb_supplementary_temp_adc";
		qcom,pre-scaling = <1 1>;
		qcom,ratiometric;
		qcom,hw-settle-time = <200>;
		qcom,scale-fn-type = <OPLUS_ADC_SCALE_HW_CALIB_DEFAULT>;
	};
	pm8550b_wls_therm { //for PM8550B_ADC5_GEN3_AMUX_THM6_GPIO10_100K_PU to config to uV
		qcom,adc-tm-type = <0>;
		qcom,scale-fn-type = <OPLUS_ADC_SCALE_HW_CALIB_DEFAULT>;
	};
	subboard_temp_adc {
		reg = <PM8550B_ADC5_GEN3_AMUX3_GPIO6_100K_PU>;
		label = "subboard_temp_adc";
		qcom,pre-scaling = <1 1>;
		qcom,ratiometric;
		qcom,hw-settle-time = <200>;
	};
	batt0_con_therm_adc {
		reg = <PM8550B_ADC5_GEN3_AMUX_THM1_BATT_THERM_100K_PU>;
		label = "batt0_con_therm_adc";
		qcom,pre-scaling = <1 1>;
		qcom,ratiometric;
		qcom,hw-settle-time = <200>;
	};
	batt1_con_therm_adc {
		reg = <PM8550B_ADC5_GEN3_AMUX4_GPIO12_100K_PU>;
		label = "batt1_con_therm_adc";
		qcom,pre-scaling = <1 1>;
		qcom,ratiometric;
		qcom,hw-settle-time = <200>;
	};
};

&pm8550vs_d_gpios {
	dischg_enable: dischg_enable {
		pins = "gpio5";
		function = "normal";
		bias-disable;
		power-source = <0>;
		output-high;
		qcom,drive-strength = <3>;
	};
	dischg_disable: dischg_disable {
		pins = "gpio5";
		function = "normal";
		bias-disable;
		power-source = <0>;
		output-low;
		qcom,drive-strength = <3>;
	};
};
//#endif OPLUS_FEATURE_CHG_BASIC

&soc {
	feedback_fb: feedback_fb {
		compatible = "oplus,haptic-feedback";
	};
};

&qupv3_se12_i2c {
	status = "okay";

	sc8517-charger@69{
		status = "okay";
		compatible = "sc,sc8517-master";
		reg = <0x69>;

		qcom,irq_gpio = <&tlmm 9 0x00>;

		pinctrl-names = "switch1_act_switch2_act", "switch1_sleep_switch2_sleep",
				"charging_inter_active", "charging_inter_sleep";
		pinctrl-0 = <&charging_switch1_active>;
		pinctrl-1 = <&charging_switch1_sleep>;
		pinctrl-2 = <&charging_inter_active>;
		pinctrl-3 = <&charging_inter_sleep>;

		qcom,charging_switch1-gpio = <&pm8550b_gpios 8 0x00>;
		qcom,voocphy_vbus_low = <300>;
		qcom,voocphy_vbus_high = <500>;

		qcom,external_gauge_support;
		qcom,voocphy_bidirect_cp_support;
		qcom,voocphy_current_default = <91>;
		qcom,copycat_vooc_support;
		oplus,copycat_identify_algorithm = <2>;
		qcom,voocphy_bidirect_fwd_ocp = /bits/ 8 <0xFF>;

		qcom,svooc_cool_down_current_limit = <100 15 15 20 25 30 35 40 45 50 55 60 63 65 70 75 80 85 100>;
		qcom,vooc_cool_down_current_limit = <60 20 20 20 30 40 50 60>;
		qcom,abnormal_adapter_current = <91 91 50 50 40 40 30 30 20 20>;
		oplus,svooc_charge_strategy_soc = <50 75 85 95>;

		qcom,vooc_little_cold_full_voltage = <4490>;
		qcom,vooc_cool_full_voltage = <4490>;
		qcom,vooc_warm_full_voltage = <4130>;
		qcom,vooc_1time_full_voltage = <4500>;
		qcom,vooc_ntime_full_voltage = <4490>;
		qcom,low_curr_full_t1 = <120>;
		qcom,low_curr_full_t2 = <250>;
		qcom,low_curr_full_t3 = <430>;
		qcom,range1_low_curr_full = <850 4490
						750 4480
						650 4470
						550 4460
						450 4450>;
		qcom,range2_low_curr_full = <1900 4490
						1800 4485
						1600 4470
						1400 4460
						1200 4450>;

		qcom,vooc_multistep_initial_batt_temp = <1000>;
		qcom,vooc_little_cool_temp = <200>;
		qcom,vooc_cool_temp = <120>;
		qcom,vooc_little_cold_temp = <50>;
		qcom,vooc_normal_low_temp = <350>;
		qcom,vooc_strategy_normal_current = <100>;
		qcom,vooc_normal_to_little_cool_current = <100>;
		qcom,vooc_batt_over_high_temp = <510>;
		qcom,vooc-low-temp = <0>;
		qcom,vooc-high-temp = <500>;
		qcom,vooc-low-soc = <0>;
		qcom,vooc-high-soc = <95>;
		qcom,vooc-normal-high-temp = <440>;
		qcom,vooc-warm-allow-vol = <4000>;
		qcom,vooc-warm-allow-soc = <50>;
		qcom,impedance_calculation_newmethod;
		qcom,svooc_circuit_r_l = <0x18>;
		qcom,svooc_circuit_r_h = <0x2>;/* 65 mR */

		qcom,vooc_strategy1_batt_high_temp0 = <420>;
		qcom,vooc_strategy1_batt_high_temp1 = <430>;
		qcom,vooc_strategy1_batt_high_temp2 = <440>;
		qcom,vooc_strategy1_batt_low_temp2 = <430>;
		qcom,vooc_strategy1_batt_low_temp1 = <420>;
		qcom,vooc_strategy1_batt_low_temp0 = <400>;

		qcom,vooc_strategy1_high_current0 = <50>;
		qcom,vooc_strategy1_high_current1 = <40>;
		qcom,vooc_strategy1_high_current2 = <20>;
		qcom,vooc_strategy1_low_current2 = <40>;
		qcom,vooc_strategy1_low_current1 = <50>;
		qcom,vooc_strategy1_low_current0 = <91>;

		qcom,voocphy_ibat_over_current = <9500>;
		qcom,voocphy_cp_max_ibus = <9500>;
		qcom,voocphy_svooc_cp_max_ibus = <3500>;
		qcom,voocphy_vooc_cp_max_ibus = <3500>;
		qcom,batt_pwd_curr_thd1 = <3200>;
		qcom,batt_pwd_vol_thd1 = <4490>;

		qcom,voocphy_freq_mincore = <940800>;
		qcom,voocphy_freq_midcore = <1440000>;
		qcom,voocphy_freq_maxcore = <1538000>;
		qcom,voocphy_current_change_timeout = <100>;

		svooc_batt_sys_curve = <1 0 1 0 0 0 0	// 8000mA
							1 1 0 0 1 1 1	// 4434mV
							0 1 1 1 1 0 0	// 6000mA
							1 1 0 1 1 0 0	// 4484mV
							0 0 1 1 1 1 0	// 3000mA
							1 1 0 1 1 0 0>; // 4484mV



		vooc_batt_sys_curve =  <0 1 0 1 1 0 1 	// 3000mA
					0 0 0 0 0 0 1	// 3414mV
					0 0 1 0 1 0 0	// 2000mA
					1 1 0 1 0 0 1	// 4454mV
					0 0 0 1 0 1 0	// 1000mA
					1 1 0 1 1 0 0>; // 4484mV

		svooc_charge_strategy {
			strategy_soc_0_to_50 {
				strategy_temp_little_cold =	<4154 26 0 0 0
								4204 22 0 0 0
								4204 20 0 0 0
								4204 15 0 0 0
								4484 13 0 0 0
								4490 10 1 0 0>;
				strategy_temp_cool =		<4154 26 0 0 0
								4204 22 0 0 0
								4204 20 0 0 0
								4204 15 0 0 0
								4484 13 0 0 0
								4490 10 1 0 0>;
				strategy_temp_little_cool = 	<4154 60 0 1200 0
								4154 55 0 1200 0
								4154 50 0 1200 0
								4154 45 0 1200 0
								4434 40 0 0 0
								4434 35 0 0 0
								4434 30 0 0 0
								4484 28 0 0 0
								4484 25 0 0 0
								4484 20 0 0 0
								4484 15 0 0 0
								4484 10 0 0 0
								4490 9 1 0 0>;
				strategy_temp_normal_low =	<4434 91 0 180 0
								4434 80 0 180 0
								4484 73 0 600 0
								4484 60 0 0 0
								4484 50 0 0 0
								4484 45 0 0 0
								4484 40 0 0 0
								4484 35 0 0 0
								4484 30 0 0 0
								4484 25 0 0 0
								4490 20 1 0 0>;
				strategy_temp_normal_high =	<4434 91 0 180 0
								4434 80 0 180 0
								4484 73 0 600 0
								4484 60 0 0 0
								4484 50 0 0 0
								4484 45 0 0 0
								4484 40 0 0 0
								4484 35 0 0 0
								4490 30 1 0 0>;
				strategy_temp_warm =		<4130 12 1 0 0>;
			};

			strategy_soc_50_to_75 {
				strategy_temp_little_cold =	<4154 26 0 0 0
								4204 22 0 0 0
								4204 20 0 0 0
								4204 15 0 0 0
								4484 13 0 0 0
								4490 10 1 0 0>;
				strategy_temp_cool =		<4154 26 0 0 0
								4204 22 0 0 0
								4204 20 0 0 0
								4204 15 0 0 0
								4484 13 0 0 0
								4490 10 1 0 0>;
				strategy_temp_little_cool =	<4154 50 0 1200 0
								4154 45 0 1200 0
								4434 40 0 0 0
								4434 35 0 0 0
								4434 30 0 0 0
								4484 28 0 0 0
								4484 25 0 0 0
								4484 20 0 0 0
								4484 15 0 0 0
								4484 10 0 0 0
								4490 9 1 0 0>;
				strategy_temp_normal_low =	<4484 60 0 2160 0
								4484 55 0 0 0
								4484 50 0 0 0
								4484 45 0 0 0
								4484 40 0 0 0
								4484 35 0 0 0
								4484 30 0 0 0
								4484 25 0 0 0
								4490 20 1 0 0>;
				strategy_temp_normal_high =	<4484 60 0 2160 0
								4484 55 0 0 0
								4484 50 0 0 0
								4484 45 0 0 0
								4484 40 0 0 0
								4484 35 0 0 0
								4490 30 1 0 0>;
				strategy_temp_warm =		<4130 12 1 0 0>;
			};

			strategy_soc_75_to_85 {
				strategy_temp_little_cold = 	<4154 26 0 0 0
								4204 22 0 0 0
								4204 20 0 0 0
								4204 15 0 0 0
								4484 13 0 0 0
								4490 10 1 0 0>;
				strategy_temp_cool =		<4154 26 0 0 0
								4204 22 0 0 0
								4204 20 0 0 0
								4204 15 0 0 0
								4484 13 0 0 0
								4490 10 1 0 0>;
				strategy_temp_little_cool =	<4434 40 0 0 0
								4434 35 0 0 0
								4434 30 0 0 0
								4484 28 0 0 0
								4484 25 0 0 0
								4484 20 0 0 0
								4484 15 0 0 0
								4484 10 0 0 0
								4490 9 1 0 0>;
				strategy_temp_normal_low =	<4484 45 0 0 0
								4484 40 0 0 0
								4484 35 0 0 0
								4484 30 0 0 0
								4484 25 0 0 0
								4490 20 1 0 0>;
				strategy_temp_normal_high =	<4484 45 0 0 0
								4484 40 0 0 0
								4484 35 0 0 0
								4490 30 1 0 0>;
				strategy_temp_warm =		<4130 12 1 0 0>;
			};

			strategy_soc_85_to_90 {
				strategy_temp_little_cold = 	< 4484 13 0 0 0
								4490 10 1 0 0>;
				strategy_temp_cool =		< 4484 13 0 0 0
								4490 10 1 0 0>;
				strategy_temp_little_cool =	< 4484 25 0 0 0
								4484 20 0 0 0
								4484 15 0 0 0
								4484 10 0 0 0
								4490 9 1 0 0>;
				strategy_temp_normal_low =	< 4484 30 0 0 0
								4484 25 0 0 0
								4490 20 1 0 0>;
				strategy_temp_normal_high =	< 4490 30 1 0 0>;
				strategy_temp_warm =		<4130 12 1 0 0>;
			};
		};

		vooc_charge_strategy {
			strategy_soc_0_to_50 {
				strategy_temp_little_cold = 	<4430 20 1 0 0>;
				strategy_temp_cool =		<4420 30 0 0 0
								 4430 20 1 0 0>;
				strategy_temp_little_cool =	<4475 30 0 0 0
								 4480 20 1 0 0>;
				strategy_temp_normal_low =	<4475 30 0 0 0
								 4480 20 1 0 0>;
				strategy_temp_normal_high =	<4475 30 0 0 0
								 4480 20 1 0 0>;
				strategy_temp_warm =		<4130 24 1 0 0>;
			};

			strategy_soc_50_to_75 {
				strategy_temp_little_cold =	<4430 20 1 0 0>;
				strategy_temp_cool =		<4420 30 0 0 0
								 4430 20 1 0 0>;
				strategy_temp_little_cool =	<4475 30 0 0 0
								 4480 20 1 0 0>;
				strategy_temp_normal_low =	<4475 30 0 0 0
								 4480 20 1 0 0>;
				strategy_temp_normal_high =	<4475 30 0 0 0
								 4480 20 1 0 0>;
				strategy_temp_warm =		<4130 24 1 0 0>;
			};

			strategy_soc_75_to_85 {
				strategy_temp_little_cold =	<4430 20 1 0 0>;
				strategy_temp_cool =		<4430 20 1 0 0>;
				strategy_temp_little_cool =	<4480 20 1 0 0>;
				strategy_temp_normal_low =	<4475 30 0 0 0
								 4480 20 1 0 0>;
				strategy_temp_normal_high =	<4475 30 0 0 0
								 4480 20 1 0 0>;
				strategy_temp_warm =		<4130 24 1 0 0>;
			};

			strategy_soc_85_to_90 {
				strategy_temp_little_cold =	<4430 20 1 0 0>;
				strategy_temp_cool =		<4430 20 1 0 0>;
				strategy_temp_little_cool =	<4480 20 1 0 0>;
				strategy_temp_normal_low =	<4480 20 1 0 0>;
				strategy_temp_normal_high =	<4480 20 1 0 0>;
				strategy_temp_warm =		<4130 24 1 0 0>;
			};
		};
	};
};

//endif OPLUS_FEATURE_CHG_BASIC

/*#ifdef OPLUS_FEATURE_CHG_BASIC*/
/* BSP.CHG.Basic, 2021/09/20, Add for pps 240 */
&qupv3_se9_i2c {
	status = "ok";
	qcom,clk-freq-out = <400000>;

	sc8571-master@66 {
		status = "okay";
		compatible = "oplus,sc8571-master";
		reg = <0x66 0>;

		qcom,ucp_gpio = <&tlmm 14 0x00>;
		pinctrl-names = "ucp_int_active", "ucp_int_sleep";
		pinctrl-0 = <&ucp_int_active>;
		pinctrl-1 = <&ucp_int_sleep>;
	};

	sc8571-slave@65 {
		status = "okay";
		compatible = "oplus,sc8571-slave";
		reg = <0x65 0>;
	};

	sc8571-slave-b@67 {
		status = "okay";
		compatible = "oplus,sc8571-slave-b";
		reg = <0x67 0>;
	};

};

&soc {
	oplus_battery_log: oplus,battery_log {
		compatible = "oplus,battery_log";
		oplus,battery_log_support;
	};
	oplus,track-charge {
		compatible = "oplus,track-charge";
		track,fast_chg_break_t_thd = <1000>;
		track,general_chg_break_t_thd = <200>;
		track,voocphy_type = <2>;
		track,wired_max_power = <240000>;
		track,wired_fast_chg_scheme = <0>;
	};
	usb_nop_phy: usb_nop_phy {
		compatible = "usb-nop-xceiv";
	};
};
/*endif OPLUS_FEATURE_CHG_BASIC*/
